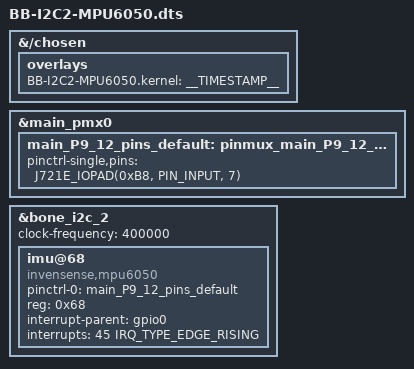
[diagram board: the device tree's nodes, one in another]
// SPDX-License-Identifier: GPL-2.0-only
/*
 * Copyright (C) 2022 Robert Nelson <robertcnelson@gmail.com>
 */

/dts-v1/;
/plugin/;

#include <dt-bindings/pinctrl/k3.h>
#include <dt-bindings/gpio/gpio.h>
#include <dt-bindings/interrupt-controller/irq.h>

/*
 * Helper to show loaded overlays under: /proc/device-tree/chosen/overlays/
 */
&{/chosen} {
	overlays {
		BB-I2C2-MPU6050.kernel = __TIMESTAMP__;
	};
};

&main_pmx0 {
	main_P9_12_pins_default: pinmux_main_P9_12_pins_default {
		pinctrl-single,pins = <
			J721E_IOPAD(0xB8, PIN_INPUT, 7)	/* AE27: PRG0_PRU0_GPO2 AE27_MCASP0_ACLKR */
		>;
	};
};

&bone_i2c_2 {
	status = "okay";

	clock-frequency = <400000>;

	#address-cells = <1>;
	#size-cells = <0>;

	imu@68 {
		pinctrl-names = "default";
		pinctrl-0 = <&main_P9_12_pins_default>;
		compatible = "invensense,mpu6050";
		reg = <0x68>;
		interrupt-parent = <&gpio0>;
		interrupts = <45 IRQ_TYPE_EDGE_RISING>;
	};
};
